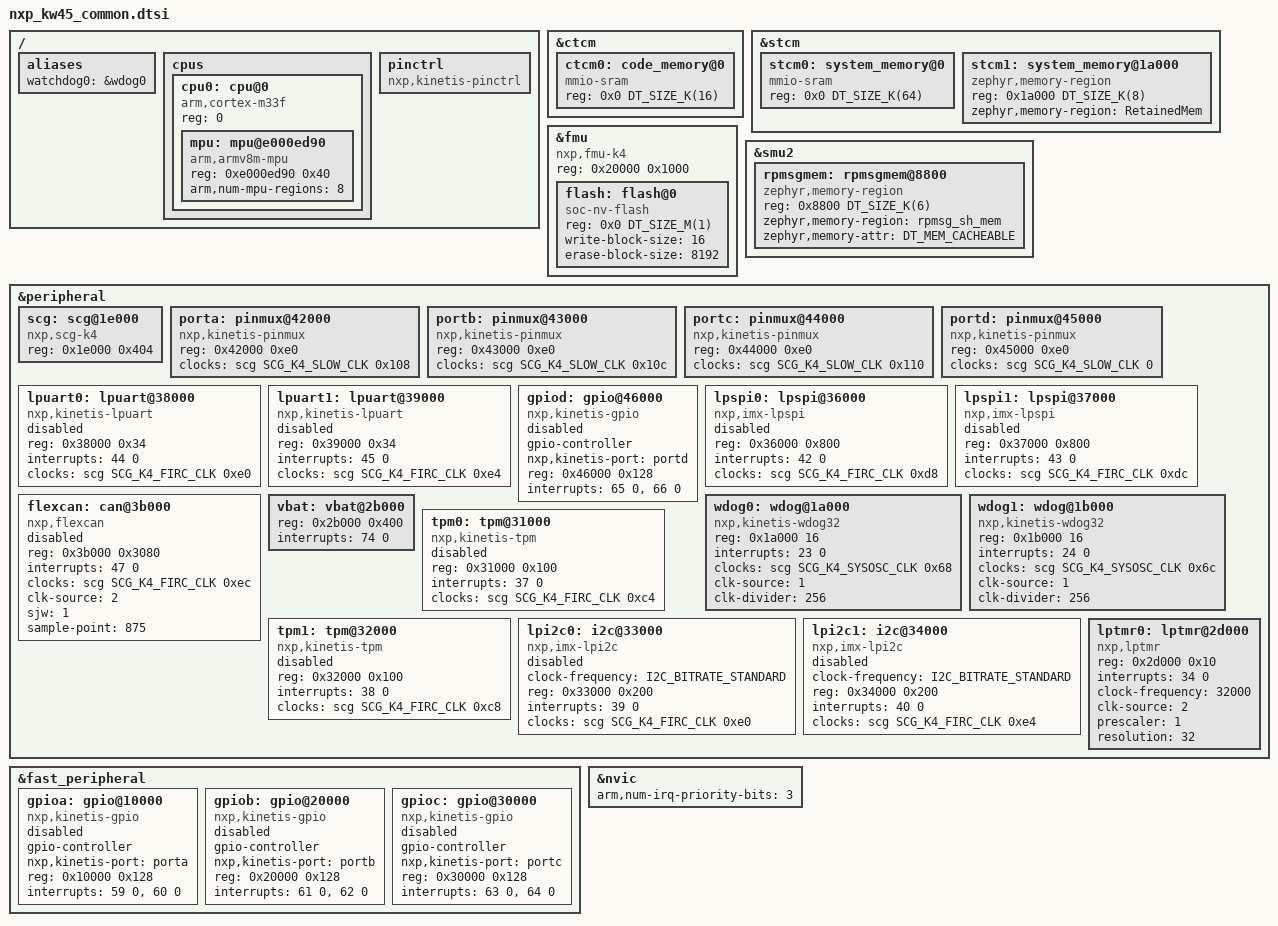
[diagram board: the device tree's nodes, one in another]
/* Copyright 2023 NXP
 *
 *
 * SPDX-License-Identifier: Apache-2.0
 */

#include <mem.h>
#include <arm/armv8-m.dtsi>
#include <zephyr/dt-bindings/clock/scg_k4.h>
#include <zephyr/dt-bindings/gpio/gpio.h>
#include <zephyr/dt-bindings/pwm/pwm.h>
#include <zephyr/dt-bindings/i2c/i2c.h>
#include <zephyr/dt-bindings/memory-attr/memory-attr.h>

/ {
	aliases {
		watchdog0 = &wdog0;
	};

	cpus {
		#address-cells = <1>;
		#size-cells = <0>;

		cpu0: cpu@0 {
			compatible = "arm,cortex-m33f";
			reg = <0>;
			#address-cells = <1>;
			#size-cells = <1>;

			mpu: mpu@e000ed90 {
				compatible = "arm,armv8m-mpu";
				reg = <0xe000ed90 0x40>;
				arm,num-mpu-regions = <8>;
			};
		};
	};

	pinctrl: pinctrl {
		compatible = "nxp,kinetis-pinctrl";
	};
};


&ctcm {
	#address-cells = <1>;
	#size-cells = <1>;

	ctcm0: code_memory@0 {
		compatible = "mmio-sram";
		reg = <0x0 DT_SIZE_K(16)>;
	};
};

&stcm {
	#address-cells = <1>;
	#size-cells = <1>;

	stcm0: system_memory@0 {
		compatible = "mmio-sram";
		reg = <0x0 DT_SIZE_K(64)>;
	};

	stcm1: system_memory@1a000 {
		compatible = "zephyr,memory-region","mmio-sram";
		reg = <0x1a000 DT_SIZE_K(8)>;
		zephyr,memory-region = "RetainedMem";
	};
};

&fmu {
	#address-cells = <1>;
	#size-cells = <1>;

	compatible = "nxp,fmu-k4";
	reg = <0x20000 0x1000>;


	flash: flash@0 {
		reg = <0x0 DT_SIZE_M(1)>;
		compatible = "soc-nv-flash";
		write-block-size = <16>;
		erase-block-size = <8192>;
	};
};

&smu2 {
	#address-cells = <1>;
	#size-cells = <1>;

	rpmsgmem: rpmsgmem@8800 {
		compatible = "zephyr,memory-region","mmio-sram";
		reg = <0x8800 DT_SIZE_K(6)>;
		zephyr,memory-region = "rpmsg_sh_mem";
		// zephyr,memory-region-mpu = "RAM";
		zephyr,memory-attr = <DT_MEM_CACHEABLE>;
	};
};

&peripheral {
	#address-cells = <1>;
	#size-cells = <1>;

	scg: scg@1e000 {
		compatible = "nxp,scg-k4";
		reg = <0x1e000 0x404>;
		#clock-cells = <2>;
	};

	porta: pinmux@42000 {
		compatible = "nxp,kinetis-pinmux";
		reg = <0x42000 0xe0>;
		clocks = <&scg SCG_K4_SLOW_CLK 0x108>;
	};

	portb: pinmux@43000 {
		compatible = "nxp,kinetis-pinmux";
		reg = <0x43000 0xe0>;
		clocks = <&scg SCG_K4_SLOW_CLK 0x10c>;
	};

	portc: pinmux@44000 {
		compatible = "nxp,kinetis-pinmux";
		reg = <0x44000 0xe0>;
		clocks = <&scg SCG_K4_SLOW_CLK 0x110>;
	};

	portd: pinmux@45000 {
		compatible = "nxp,kinetis-pinmux";
		reg = <0x45000 0xe0>;
		clocks = <&scg SCG_K4_SLOW_CLK 0>;
	};

	lpuart0: lpuart@38000 {
		compatible = "nxp,kinetis-lpuart";
		reg = <0x38000 0x34>;
		interrupts = <44 0>;
		clocks = <&scg SCG_K4_FIRC_CLK 0xe0>;
		status = "disabled";
	};

	lpuart1: lpuart@39000 {
		compatible = "nxp,kinetis-lpuart";
		reg = <0x39000 0x34>;
		interrupts = <45 0>;
		clocks = <&scg SCG_K4_FIRC_CLK 0xe4>;
		status = "disabled";
	};

	gpiod: gpio@46000{
		compatible = "nxp,kinetis-gpio";
		status = "disabled";
		gpio-controller;
		#gpio-cells = <2>;
		nxp,kinetis-port = <&portd>;
		reg = <0x46000 0x128>;
		interrupts = <65 0>, <66 0>;
	};

	lpspi0: lpspi@36000 {
		compatible = "nxp,imx-lpspi";
		reg = <0x36000 0x800>;
		interrupts = <42 0>;
		clocks = <&scg SCG_K4_FIRC_CLK 0xd8>;
		#address-cells = <1>;
		#size-cells = <0>;
		status = "disabled";
	};

	lpspi1: lpspi@37000 {
		compatible = "nxp,imx-lpspi";
		reg = <0x37000 0x800>;
		interrupts = <43 0>;
		clocks = <&scg SCG_K4_FIRC_CLK 0xdc>;
		#address-cells = <1>;
		#size-cells = <0>;
		status = "disabled";
	};

	flexcan: can@3b000 {
		compatible = "nxp,flexcan";
		reg = <0x3b000 0x3080>;
		interrupts = <47 0>;
		interrupt-names = "common";
		clocks = <&scg SCG_K4_FIRC_CLK 0xec>;
		clk-source = <2>;
		sjw = <1>;
		sample-point = <875>;
		status = "disabled";
	};

	wdog0: wdog@1a000 {
		compatible = "nxp,kinetis-wdog32";
		reg = <0x1a000 16>;
		interrupts = <23 0>;
		clocks = <&scg SCG_K4_SYSOSC_CLK 0x68>;
		clk-source = <1>;
		clk-divider = <256>;
	};

	wdog1: wdog@1b000 {
		compatible = "nxp,kinetis-wdog32";
		reg = <0x1b000 16>;
		interrupts = <24 0>;
		clocks = <&scg SCG_K4_SYSOSC_CLK 0x6c>;
		clk-source = <1>;
		clk-divider = <256>;
	};

	vbat: vbat@2b000 {
		reg = <0x2b000 0x400>;
		interrupts = <74 0>;
	};

	tpm0: tpm@31000 {
		compatible = "nxp,kinetis-tpm";
		reg = <0x31000 0x100>;
		interrupts = <37 0>;
		clocks = <&scg SCG_K4_FIRC_CLK 0xc4>;
		status = "disabled";
		#pwm-cells = <3>;
	};

	tpm1: tpm@32000 {
		compatible = "nxp,kinetis-tpm";
		reg = <0x32000 0x100>;
		interrupts = <38 0>;
		clocks = <&scg SCG_K4_FIRC_CLK 0xc8>;
		status = "disabled";
		#pwm-cells = <3>;
	};

	lpi2c0: i2c@33000 {
		compatible = "nxp,imx-lpi2c";
		clock-frequency = <I2C_BITRATE_STANDARD>;
		#address-cells = <1>;
		#size-cells = <0>;
		reg = <0x33000 0x200>;
		interrupts = <39 0>;
		clocks = <&scg SCG_K4_FIRC_CLK 0xe0>;
		status = "disabled";
	};

	lpi2c1: i2c@34000 {
		compatible = "nxp,imx-lpi2c";
		clock-frequency = <I2C_BITRATE_STANDARD>;
		#address-cells = <1>;
		#size-cells = <0>;
		reg = <0x34000 0x200>;
		interrupts = <40 0>;
		clocks = <&scg SCG_K4_FIRC_CLK 0xe4>;
		status = "disabled";
	};

	lptmr0: lptmr@2d000 {
		compatible = "nxp,lptmr";
		reg = <0x2d000 0x10>;
		interrupts = <34 0>;
		clock-frequency = <32000>;
		clk-source = <2>;
		prescaler = <1>;
		resolution = <32>;
	};
};


&fast_peripheral {
	#address-cells = <1>;
	#size-cells = <1>;

	gpioa: gpio@10000{
		compatible = "nxp,kinetis-gpio";
		status = "disabled";
		gpio-controller;
		#gpio-cells = <2>;
		nxp,kinetis-port = <&porta>;
		reg = <0x10000 0x128>;
		interrupts = <59 0>, <60 0>;
	};

	gpiob: gpio@20000{
		compatible = "nxp,kinetis-gpio";
		status = "disabled";
		gpio-controller;
		#gpio-cells = <2>;
		nxp,kinetis-port = <&portb>;
		reg = <0x20000 0x128>;
		interrupts = <61 0>, <62 0>;
	};

	gpioc: gpio@30000{
		compatible = "nxp,kinetis-gpio";
		status = "disabled";
		gpio-controller;
		#gpio-cells = <2>;
		nxp,kinetis-port = <&portc>;
		reg = <0x30000 0x128>;
		interrupts = <63 0>, <64 0>;
	};
};

&nvic {
	arm,num-irq-priority-bits = <3>;
};
